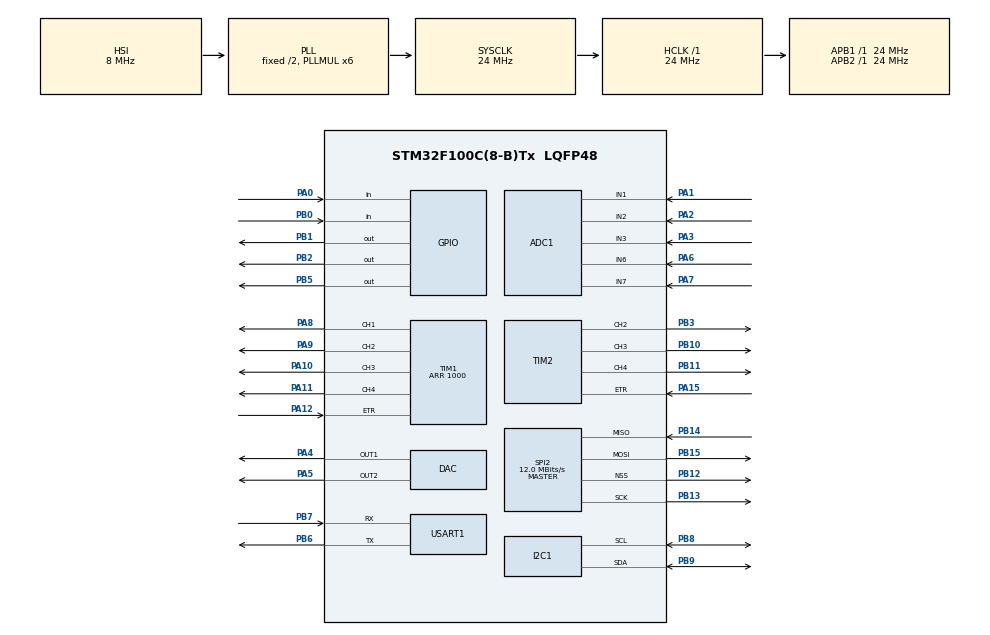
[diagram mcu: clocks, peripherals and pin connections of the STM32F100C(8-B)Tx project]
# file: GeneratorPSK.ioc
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ADC1.Channel-0\#ChannelRegularConversion=ADC_CHANNEL_1
ADC1.Channel-1\#ChannelRegularConversion=ADC_CHANNEL_2
ADC1.Channel-2\#ChannelRegularConversion=ADC_CHANNEL_3
ADC1.Channel-3\#ChannelRegularConversion=ADC_CHANNEL_6
ADC1.Channel-4\#ChannelRegularConversion=ADC_CHANNEL_7
ADC1.NbrOfConversion=5
ADC1.NbrOfConversionFlag=1
ADC1.Rank-0\#ChannelRegularConversion=1
ADC1.Rank-1\#ChannelRegularConversion=2
ADC1.Rank-2\#ChannelRegularConversion=3
ADC1.Rank-3\#ChannelRegularConversion=4
ADC1.Rank-4\#ChannelRegularConversion=5
ADC1.SamplingTime-0\#ChannelRegularConversion=ADC_SAMPLETIME_1CYCLE_5
ADC1.SamplingTime-1\#ChannelRegularConversion=ADC_SAMPLETIME_1CYCLE_5
ADC1.SamplingTime-2\#ChannelRegularConversion=ADC_SAMPLETIME_1CYCLE_5
ADC1.SamplingTime-3\#ChannelRegularConversion=ADC_SAMPLETIME_1CYCLE_5
ADC1.SamplingTime-4\#ChannelRegularConversion=ADC_SAMPLETIME_1CYCLE_5
ADC1.master=1
DAC.DAC_Trigger=DAC_TRIGGER_SOFTWARE
DAC.DAC_Trigger2=DAC_TRIGGER_SOFTWARE
Dma.ADC1.0.Direction=DMA_PERIPH_TO_MEMORY
Dma.ADC1.0.Instance=DMA1_Channel1
Dma.ADC1.0.MemDataAlignment=DMA_MDATAALIGN_HALFWORD
Dma.ADC1.0.MemInc=DMA_MINC_ENABLE
Dma.ADC1.0.Mode=DMA_CIRCULAR
Dma.ADC1.0.PeriphDataAlignment=DMA_PDATAALIGN_HALFWORD
Dma.ADC1.0.PeriphInc=DMA_PINC_DISABLE
Dma.ADC1.0.Priority=DMA_PRIORITY_LOW
Dma.Request0=ADC1
FREERTOS.Tasks01=defaultTask,0,128,StartDefaultTask,Default,NULL,Dynamic,NULL,NULL;userDisplay,-3,128,userDisplayTask,Default,NULL,Dynamic,NULL,NULL
Mcu.Family=STM32F1
Mcu.Name=STM32F100C(8-B)Tx
Mcu.Package=LQFP48
NVIC.DMA1_Channel1_IRQn=true\:5\:0\:false\:false\:true\:true\:false\:true
NVIC.PriorityGroup=NVIC_PRIORITYGROUP_4
NVIC.RCC_IRQn=true\:5\:0\:false\:false\:true\:true\:true\:false
NVIC.TIM1_UP_TIM16_IRQn=true\:5\:0\:false\:false\:true\:true\:true\:true
NVIC.TIM7_IRQn=true\:0\:0\:false\:false\:true\:false\:false\:true
NVIC.TimeBase=TIM7_IRQn
NVIC.TimeBaseIP=TIM7
PA0-WKUP.GPIO_PuPd=GPIO_PULLDOWN
PA0-WKUP.Signal=GPIO_Input
PA1.Signal=ADCx_IN1
PA10.Signal=S_TIM1_CH3
PA11.Signal=S_TIM1_CH4
PA12.Signal=S_TIM1_ETR
PA13.Mode=Serial_Wire
PA13.Signal=SYS_JTMS-SWDIO
PA14.Mode=Serial_Wire
PA14.Signal=SYS_JTCK-SWCLK
PA15.Signal=S_TIM2_CH1_ETR
PA2.Signal=ADCx_IN2
PA3.Signal=ADCx_IN3
PA4.Signal=COMP_DAC1_group
PA5.Signal=COMP_DAC2_group
PA6.Signal=ADCx_IN6
PA7.Signal=ADCx_IN7
PA8.Signal=S_TIM1_CH1
PA9.Signal=S_TIM1_CH2
PB0.Signal=GPIO_Input
PB1.Signal=GPIO_Output
PB10.Signal=S_TIM2_CH3
PB11.Signal=S_TIM2_CH4
PB12.Mode=NSS_Signal_Hard_Output
PB12.Signal=SPI2_NSS
PB13.Mode=Full_Duplex_Master
PB13.Signal=SPI2_SCK
PB14.Mode=Full_Duplex_Master
PB14.Signal=SPI2_MISO
PB15.Mode=Full_Duplex_Master
PB15.Signal=SPI2_MOSI
PB2.Signal=GPIO_Output
PB3.Signal=S_TIM2_CH2
PB5.Signal=GPIO_Output
PB6.Mode=Asynchronous
PB6.Signal=USART1_TX
PB7.Mode=Asynchronous
PB7.Signal=USART1_RX
PB8.Mode=I2C
PB8.Signal=I2C1_SCL
PB9.Mode=I2C
PB9.Signal=I2C1_SDA
ProjectManager.HeapSize=0x200
ProjectManager.StackSize=0x400
ProjectManager.TargetToolchain=SW4STM32
RCC.AHBFreq_Value=24000000
RCC.APB1Freq_Value=24000000
RCC.APB1TimFreq_Value=24000000
RCC.APB2Freq_Value=24000000
RCC.APB2TimFreq_Value=24000000
RCC.HCLKFreq_Value=24000000
RCC.PLLMUL=RCC_PLL_MUL6
RCC.SYSCLKFreq_VALUE=24000000
RCC.SYSCLKSource=RCC_SYSCLKSOURCE_PLLCLK
SH.ADCx_IN1.0=ADC1_IN1,IN1
SH.ADCx_IN2.0=ADC1_IN2,IN2
SH.ADCx_IN3.0=ADC1_IN3,IN3
SH.ADCx_IN6.0=ADC1_IN6,IN6
SH.ADCx_IN7.0=ADC1_IN7,IN7
SH.COMP_DAC1_group.0=DAC_OUT1,DAC_OUT1
SH.COMP_DAC2_group.0=DAC_OUT2,DAC_OUT2
SH.S_TIM1_CH1.0=TIM1_CH1,PWM Generation1 CH1
SH.S_TIM1_CH2.0=TIM1_CH2,PWM Generation2 CH2
SH.S_TIM1_CH3.0=TIM1_CH3,PWM Generation3 CH3
SH.S_TIM1_CH4.0=TIM1_CH4,PWM Generation4 CH4
SH.S_TIM1_ETR.0=TIM1_ETR,ClockSourceETR_Mode2
SH.S_TIM2_CH1_ETR.0=TIM2_ETR,ClockSourceETR_Mode2
SH.S_TIM2_CH2.0=TIM2_CH2,PWM Generation2 CH2
SH.S_TIM2_CH3.0=TIM2_CH3,PWM Generation3 CH3
SH.S_TIM2_CH4.0=TIM2_CH4,PWM Generation4 CH4
SPI2.CalculateBaudRate=12.0 MBits/s
SPI2.Direction=SPI_DIRECTION_2LINES
SPI2.Mode=SPI_MODE_MASTER
SPI2.VirtualNSS=VM_NSSHARD
SPI2.VirtualType=VM_MASTER
TIM1.AutoReloadPreload=TIM_AUTORELOAD_PRELOAD_ENABLE
TIM1.Channel-PWM\ Generation1\ CH1=TIM_CHANNEL_1
TIM1.Channel-PWM\ Generation2\ CH2=TIM_CHANNEL_2
TIM1.Channel-PWM\ Generation3\ CH3=TIM_CHANNEL_3
TIM1.Channel-PWM\ Generation4\ CH4=TIM_CHANNEL_4
TIM1.OCPolarity_1=TIM_OCPOLARITY_LOW
TIM1.OCPolarity_2=TIM_OCPOLARITY_LOW
TIM1.OCPolarity_3=TIM_OCPOLARITY_LOW
TIM1.OCPolarity_4=TIM_OCPOLARITY_LOW
TIM1.Period=1000
TIM1.TIM_MasterOutputTrigger=TIM_TRGO_ENABLE
TIM2.Channel-PWM\ Generation2\ CH2=TIM_CHANNEL_2
TIM2.Channel-PWM\ Generation3\ CH3=TIM_CHANNEL_3
TIM2.Channel-PWM\ Generation4\ CH4=TIM_CHANNEL_4
USART1.VirtualMode=VM_ASYNC
VP_FREERTOS_VS_CMSIS_V1.Mode=CMSIS_V1
VP_SYS_VS_tim7.Mode=TIM7
board=custom

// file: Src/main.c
/* USER CODE BEGIN Header */
/**
  ******************************************************************************
  * @file           : main.c
  * @brief          : Main program body
  ******************************************************************************
  * @attention
  *
  * <h2><center>&copy; Copyright (c) 2020 STMicroelectronics.
  * All rights reserved.</center></h2>
  *
  * This software component is licensed by ST under BSD 3-Clause license,
  * the "License"; You may not use this file except in compliance with the
  * License. You may obtain a copy of the License at:
  *                        opensource.org/licenses/BSD-3-Clause
  *
  ******************************************************************************
  */
/* USER CODE END Header */

#include "main.h"
#include "cmsis_os.h"

/* USER CODE BEGIN Includes */
#include "kernel.h"
/* USER CODE END Includes */

ADC_HandleTypeDef hadc1;
DMA_HandleTypeDef hdma_adc1;

DAC_HandleTypeDef hdac;

I2C_HandleTypeDef hi2c1;

SPI_HandleTypeDef hspi2;

TIM_HandleTypeDef htim1;
TIM_HandleTypeDef htim2;

UART_HandleTypeDef huart1;

osThreadId defaultTaskHandle;
osThreadId userDisplayHandle;

void SystemClock_Config(void);
static void MX_GPIO_Init(void);
static void MX_DMA_Init(void);
static void MX_ADC1_Init(void);
static void MX_DAC_Init(void);
static void MX_TIM1_Init(void);
static void MX_I2C1_Init(void);
static void MX_SPI2_Init(void);
static void MX_TIM2_Init(void);
static void MX_USART1_UART_Init(void);
void StartDefaultTask(void const * argument);
void userDisplayTask(void const * argument);

int main(void)
{

  /* MCU Configuration--------------------------------------------------------*/

  /* Reset of all peripherals, Initializes the Flash interface and the Systick. */
  HAL_Init();

  /* Configure the system clock */
  SystemClock_Config();

  /* Initialize all configured peripherals */
  MX_GPIO_Init();
  MX_DMA_Init();
  MX_ADC1_Init();
  MX_DAC_Init();
  MX_TIM1_Init();
  MX_I2C1_Init();
  MX_SPI2_Init();
  MX_TIM2_Init();
  MX_USART1_UART_Init();
  /* USER CODE BEGIN 2 */
  Kernel_Init(&htim1, &htim2, &hadc1, &hdma_adc1, &hdac);

  /* USER CODE END 2 */

  /* Create the thread(s) */
  /* definition and creation of defaultTask */
  osThreadDef(defaultTask, StartDefaultTask, osPriorityNormal, 0, 128);
  defaultTaskHandle = osThreadCreate(osThread(defaultTask), NULL);

  /* definition and creation of userDisplay */
  osThreadDef(userDisplay, userDisplayTask, osPriorityIdle, 0, 128);
  userDisplayHandle = osThreadCreate(osThread(userDisplay), NULL);

  /* Start scheduler */
  osKernelStart();

  /* We should never get here as control is now taken by the scheduler */

  /* Infinite loop */
  while (1)
  {

  }
}

void SystemClock_Config(void)
{
  RCC_OscInitTypeDef RCC_OscInitStruct = {0};
  RCC_ClkInitTypeDef RCC_ClkInitStruct = {0};
  RCC_PeriphCLKInitTypeDef PeriphClkInit = {0};

  /** Initializes the CPU, AHB and APB busses clocks
  */
  RCC_OscInitStruct.OscillatorType = RCC_OSCILLATORTYPE_HSI;
  RCC_OscInitStruct.HSIState = RCC_HSI_ON;
  RCC_OscInitStruct.HSICalibrationValue = RCC_HSICALIBRATION_DEFAULT;
  RCC_OscInitStruct.PLL.PLLState = RCC_PLL_ON;
  RCC_OscInitStruct.PLL.PLLSource = RCC_PLLSOURCE_HSI_DIV2;
  RCC_OscInitStruct.PLL.PLLMUL = RCC_PLL_MUL6;
  if (HAL_RCC_OscConfig(&RCC_OscInitStruct) != HAL_OK)
  {
    Error_Handler();
  }
  /** Initializes the CPU, AHB and APB busses clocks
  */
  RCC_ClkInitStruct.ClockType = RCC_CLOCKTYPE_HCLK|RCC_CLOCKTYPE_SYSCLK
                              |RCC_CLOCKTYPE_PCLK1|RCC_CLOCKTYPE_PCLK2;
  RCC_ClkInitStruct.SYSCLKSource = RCC_SYSCLKSOURCE_PLLCLK;
  RCC_ClkInitStruct.AHBCLKDivider = RCC_SYSCLK_DIV1;
  RCC_ClkInitStruct.APB1CLKDivider = RCC_HCLK_DIV1;
  RCC_ClkInitStruct.APB2CLKDivider = RCC_HCLK_DIV1;

  if (HAL_RCC_ClockConfig(&RCC_ClkInitStruct, FLASH_LATENCY_0) != HAL_OK)
  {
    Error_Handler();
  }
  PeriphClkInit.PeriphClockSelection = RCC_PERIPHCLK_ADC;
  PeriphClkInit.AdcClockSelection = RCC_ADCPCLK2_DIV2;
  if (HAL_RCCEx_PeriphCLKConfig(&PeriphClkInit) != HAL_OK)
  {
    Error_Handler();
  }
}

static void MX_ADC1_Init(void)
{

  ADC_ChannelConfTypeDef sConfig = {0};

  /** Common config
  */
  hadc1.Instance = ADC1;
  hadc1.Init.ScanConvMode = ADC_SCAN_ENABLE;
  hadc1.Init.ContinuousConvMode = DISABLE;
  hadc1.Init.DiscontinuousConvMode = DISABLE;
  hadc1.Init.ExternalTrigConv = ADC_SOFTWARE_START;
  hadc1.Init.DataAlign = ADC_DATAALIGN_RIGHT;
  hadc1.Init.NbrOfConversion = 5;
  if (HAL_ADC_Init(&hadc1) != HAL_OK)
  {
    Error_Handler();
  }
  /** Configure Regular Channel
  */
  sConfig.Channel = ADC_CHANNEL_1;
  sConfig.Rank = ADC_REGULAR_RANK_1;
  sConfig.SamplingTime = ADC_SAMPLETIME_1CYCLE_5;
  if (HAL_ADC_ConfigChannel(&hadc1, &sConfig) != HAL_OK)
  {
    Error_Handler();
  }
  /** Configure Regular Channel
  */
  sConfig.Channel = ADC_CHANNEL_2;
  sConfig.Rank = ADC_REGULAR_RANK_2;
  if (HAL_ADC_ConfigChannel(&hadc1, &sConfig) != HAL_OK)
  {
    Error_Handler();
  }
  /** Configure Regular Channel
  */
  sConfig.Channel = ADC_CHANNEL_3;
  sConfig.Rank = ADC_REGULAR_RANK_3;
  if (HAL_ADC_ConfigChannel(&hadc1, &sConfig) != HAL_OK)
  {
    Error_Handler();
  }
  /** Configure Regular Channel
  */
  sConfig.Channel = ADC_CHANNEL_6;
  sConfig.Rank = ADC_REGULAR_RANK_4;
  if (HAL_ADC_ConfigChannel(&hadc1, &sConfig) != HAL_OK)
  {
    Error_Handler();
  }
  /** Configure Regular Channel
  */
  sConfig.Channel = ADC_CHANNEL_7;
  sConfig.Rank = ADC_REGULAR_RANK_5;
  if (HAL_ADC_ConfigChannel(&hadc1, &sConfig) != HAL_OK)
  {
    Error_Handler();
  }

}

static void MX_DAC_Init(void)
{

  DAC_ChannelConfTypeDef sConfig = {0};

  /** DAC Initialization
  */
  hdac.Instance = DAC;
  if (HAL_DAC_Init(&hdac) != HAL_OK)
  {
    Error_Handler();
  }
  /** DAC channel OUT1 config
  */
  sConfig.DAC_Trigger = DAC_TRIGGER_SOFTWARE;
  sConfig.DAC_OutputBuffer = DAC_OUTPUTBUFFER_ENABLE;
  if (HAL_DAC_ConfigChannel(&hdac, &sConfig, DAC_CHANNEL_1) != HAL_OK)
  {
    Error_Handler();
  }
  /** DAC channel OUT2 config
  */
  if (HAL_DAC_ConfigChannel(&hdac, &sConfig, DAC_CHANNEL_2) != HAL_OK)
  {
    Error_Handler();
  }

}

static void MX_I2C1_Init(void)
{

  hi2c1.Instance = I2C1;
  hi2c1.Init.ClockSpeed = 100000;
  hi2c1.Init.DutyCycle = I2C_DUTYCYCLE_2;
  hi2c1.Init.OwnAddress1 = 0;
  hi2c1.Init.AddressingMode = I2C_ADDRESSINGMODE_7BIT;
  hi2c1.Init.DualAddressMode = I2C_DUALADDRESS_DISABLE;
  hi2c1.Init.OwnAddress2 = 0;
  hi2c1.Init.GeneralCallMode = I2C_GENERALCALL_DISABLE;
  hi2c1.Init.NoStretchMode = I2C_NOSTRETCH_DISABLE;
  if (HAL_I2C_Init(&hi2c1) != HAL_OK)
  {
    Error_Handler();
  }

}

static void MX_SPI2_Init(void)
{

  /* SPI2 parameter configuration*/
  hspi2.Instance = SPI2;
  hspi2.Init.Mode = SPI_MODE_MASTER;
  hspi2.Init.Direction = SPI_DIRECTION_2LINES;
  hspi2.Init.DataSize = SPI_DATASIZE_8BIT;
  hspi2.Init.CLKPolarity = SPI_POLARITY_LOW;
  hspi2.Init.CLKPhase = SPI_PHASE_1EDGE;
  hspi2.Init.NSS = SPI_NSS_HARD_OUTPUT;
  hspi2.Init.BaudRatePrescaler = SPI_BAUDRATEPRESCALER_2;
  hspi2.Init.FirstBit = SPI_FIRSTBIT_MSB;
  hspi2.Init.TIMode = SPI_TIMODE_DISABLE;
  hspi2.Init.CRCCalculation = SPI_CRCCALCULATION_DISABLE;
  hspi2.Init.CRCPolynomial = 10;
  if (HAL_SPI_Init(&hspi2) != HAL_OK)
  {
    Error_Handler();
  }

}

static void MX_TIM1_Init(void)
{

  TIM_ClockConfigTypeDef sClockSourceConfig = {0};
  TIM_MasterConfigTypeDef sMasterConfig = {0};
  TIM_OC_InitTypeDef sConfigOC = {0};
  TIM_BreakDeadTimeConfigTypeDef sBreakDeadTimeConfig = {0};

  htim1.Instance = TIM1;
  htim1.Init.Prescaler = 0;
  htim1.Init.CounterMode = TIM_COUNTERMODE_UP;
  htim1.Init.Period = 1000;
  htim1.Init.ClockDivision = TIM_CLOCKDIVISION_DIV1;
  htim1.Init.RepetitionCounter = 0;
  htim1.Init.AutoReloadPreload = TIM_AUTORELOAD_PRELOAD_ENABLE;
  if (HAL_TIM_Base_Init(&htim1) != HAL_OK)
  {
    Error_Handler();
  }
  sClockSourceConfig.ClockSource = TIM_CLOCKSOURCE_ETRMODE2;
  sClockSourceConfig.ClockPolarity = TIM_CLOCKPOLARITY_NONINVERTED;
  sClockSourceConfig.ClockPrescaler = TIM_CLOCKPRESCALER_DIV1;
  sClockSourceConfig.ClockFilter = 0;
  if (HAL_TIM_ConfigClockSource(&htim1, &sClockSourceConfig) != HAL_OK)
  {
    Error_Handler();
  }
  if (HAL_TIM_PWM_Init(&htim1) != HAL_OK)
  {
    Error_Handler();
  }
  sMasterConfig.MasterOutputTrigger = TIM_TRGO_ENABLE;
  sMasterConfig.MasterSlaveMode = TIM_MASTERSLAVEMODE_DISABLE;
  if (HAL_TIMEx_MasterConfigSynchronization(&htim1, &sMasterConfig) != HAL_OK)
  {
    Error_Handler();
  }
  sConfigOC.OCMode = TIM_OCMODE_PWM1;
  sConfigOC.Pulse = 0;
  sConfigOC.OCPolarity = TIM_OCPOLARITY_LOW;
  sConfigOC.OCNPolarity = TIM_OCNPOLARITY_HIGH;
  sConfigOC.OCFastMode = TIM_OCFAST_DISABLE;
  sConfigOC.OCIdleState = TIM_OCIDLESTATE_RESET;
  sConfigOC.OCNIdleState = TIM_OCNIDLESTATE_RESET;
  if (HAL_TIM_PWM_ConfigChannel(&htim1, &sConfigOC, TIM_CHANNEL_1) != HAL_OK)
  {
    Error_Handler();
  }
  if (HAL_TIM_PWM_ConfigChannel(&htim1, &sConfigOC, TIM_CHANNEL_2) != HAL_OK)
  {
    Error_Handler();
  }
  if (HAL_TIM_PWM_ConfigChannel(&htim1, &sConfigOC, TIM_CHANNEL_3) != HAL_OK)
  {
    Error_Handler();
  }
  if (HAL_TIM_PWM_ConfigChannel(&htim1, &sConfigOC, TIM_CHANNEL_4) != HAL_OK)
  {
    Error_Handler();
  }
  sBreakDeadTimeConfig.OffStateRunMode = TIM_OSSR_DISABLE;
  sBreakDeadTimeConfig.OffStateIDLEMode = TIM_OSSI_DISABLE;
  sBreakDeadTimeConfig.LockLevel = TIM_LOCKLEVEL_OFF;
  sBreakDeadTimeConfig.DeadTime = 0;
  sBreakDeadTimeConfig.BreakState = TIM_BREAK_DISABLE;
  sBreakDeadTimeConfig.BreakPolarity = TIM_BREAKPOLARITY_HIGH;
  sBreakDeadTimeConfig.AutomaticOutput = TIM_AUTOMATICOUTPUT_DISABLE;
  if (HAL_TIMEx_ConfigBreakDeadTime(&htim1, &sBreakDeadTimeConfig) != HAL_OK)
  {
    Error_Handler();
  }
  HAL_TIM_MspPostInit(&htim1);

}

static void MX_TIM2_Init(void)
{

  TIM_ClockConfigTypeDef sClockSourceConfig = {0};
  TIM_MasterConfigTypeDef sMasterConfig = {0};
  TIM_OC_InitTypeDef sConfigOC = {0};

  htim2.Instance = TIM2;
  htim2.Init.Prescaler = 0;
  htim2.Init.CounterMode = TIM_COUNTERMODE_UP;
  htim2.Init.Period = 0;
  htim2.Init.ClockDivision = TIM_CLOCKDIVISION_DIV1;
  htim2.Init.AutoReloadPreload = TIM_AUTORELOAD_PRELOAD_DISABLE;
  if (HAL_TIM_Base_Init(&htim2) != HAL_OK)
  {
    Error_Handler();
  }
  sClockSourceConfig.ClockSource = TIM_CLOCKSOURCE_ETRMODE2;
  sClockSourceConfig.ClockPolarity = TIM_CLOCKPOLARITY_NONINVERTED;
  sClockSourceConfig.ClockPrescaler = TIM_CLOCKPRESCALER_DIV1;
  sClockSourceConfig.ClockFilter = 0;
  if (HAL_TIM_ConfigClockSource(&htim2, &sClockSourceConfig) != HAL_OK)
  {
    Error_Handler();
  }
  if (HAL_TIM_PWM_Init(&htim2) != HAL_OK)
  {
    Error_Handler();
  }
  sMasterConfig.MasterOutputTrigger = TIM_TRGO_RESET;
  sMasterConfig.MasterSlaveMode = TIM_MASTERSLAVEMODE_DISABLE;
  if (HAL_TIMEx_MasterConfigSynchronization(&htim2, &sMasterConfig) != HAL_OK)
  {
    Error_Handler();
  }
  sConfigOC.OCMode = TIM_OCMODE_PWM1;
  sConfigOC.Pulse = 0;
  sConfigOC.OCPolarity = TIM_OCPOLARITY_HIGH;
  sConfigOC.OCFastMode = TIM_OCFAST_DISABLE;
  if (HAL_TIM_PWM_ConfigChannel(&htim2, &sConfigOC, TIM_CHANNEL_2) != HAL_OK)
  {
    Error_Handler();
  }
  if (HAL_TIM_PWM_ConfigChannel(&htim2, &sConfigOC, TIM_CHANNEL_3) != HAL_OK)
  {
    Error_Handler();
  }
  if (HAL_TIM_PWM_ConfigChannel(&htim2, &sConfigOC, TIM_CHANNEL_4) != HAL_OK)
  {
    Error_Handler();
  }
  HAL_TIM_MspPostInit(&htim2);

}

static void MX_USART1_UART_Init(void)
{

  huart1.Instance = USART1;
  huart1.Init.BaudRate = 115200;
  huart1.Init.WordLength = UART_WORDLENGTH_8B;
  huart1.Init.StopBits = UART_STOPBITS_1;
  huart1.Init.Parity = UART_PARITY_NONE;
  huart1.Init.Mode = UART_MODE_TX_RX;
  huart1.Init.HwFlowCtl = UART_HWCONTROL_NONE;
  huart1.Init.OverSampling = UART_OVERSAMPLING_16;
  if (HAL_UART_Init(&huart1) != HAL_OK)
  {
    Error_Handler();
  }

}

static void MX_DMA_Init(void)
{

  /* DMA controller clock enable */
  __HAL_RCC_DMA1_CLK_ENABLE();

  /* DMA interrupt init */
  /* DMA1_Channel1_IRQn interrupt configuration */
  HAL_NVIC_SetPriority(DMA1_Channel1_IRQn, 5, 0);
  HAL_NVIC_EnableIRQ(DMA1_Channel1_IRQn);

}

static void MX_GPIO_Init(void)
{
  GPIO_InitTypeDef GPIO_InitStruct = {0};

  /* GPIO Ports Clock Enable */
  __HAL_RCC_GPIOA_CLK_ENABLE();
  __HAL_RCC_GPIOB_CLK_ENABLE();

  /*Configure GPIO pin Output Level */
  HAL_GPIO_WritePin(GPIOB, GPIO_PIN_1|GPIO_PIN_2|GPIO_PIN_5, GPIO_PIN_RESET);

  /*Configure GPIO pin : PA0 */
  GPIO_InitStruct.Pin = GPIO_PIN_0;
  GPIO_InitStruct.Mode = GPIO_MODE_INPUT;
  GPIO_InitStruct.Pull = GPIO_PULLDOWN;
  HAL_GPIO_Init(GPIOA, &GPIO_InitStruct);

  /*Configure GPIO pin : PB0 */
  GPIO_InitStruct.Pin = GPIO_PIN_0;
  GPIO_InitStruct.Mode = GPIO_MODE_INPUT;
  GPIO_InitStruct.Pull = GPIO_NOPULL;
  HAL_GPIO_Init(GPIOB, &GPIO_InitStruct);

  /*Configure GPIO pins : PB1 PB2 PB5 */
  GPIO_InitStruct.Pin = GPIO_PIN_1|GPIO_PIN_2|GPIO_PIN_5;
  GPIO_InitStruct.Mode = GPIO_MODE_OUTPUT_PP;
  GPIO_InitStruct.Pull = GPIO_NOPULL;
  GPIO_InitStruct.Speed = GPIO_SPEED_FREQ_LOW;
  HAL_GPIO_Init(GPIOB, &GPIO_InitStruct);

}

void StartDefaultTask(void const * argument)
{
  /* USER CODE BEGIN 5 */

	Kernel_Task();
  /* Infinite loop */
  for(;;)
  {

    osDelay(1);
  }
  /* USER CODE END 5 */
}

void userDisplayTask(void const * argument)
{
  /* USER CODE BEGIN userDisplayTask */
	UserDisplayTask();
  /* Infinite loop */
  for(;;)
  {
    osDelay(1);
  }
  /* USER CODE END userDisplayTask */
}

void HAL_TIM_PeriodElapsedCallback(TIM_HandleTypeDef *htim)
{
  if (htim->Instance == TIM7) {
    HAL_IncTick();
  }
  /* USER CODE BEGIN Callback 1 */
  TIM1_PeriodElapsedCallback();
  /* USER CODE END Callback 1 */
}

void Error_Handler(void)
{
}

/************************ (C) COPYRIGHT STMicroelectronics *****END OF FILE****/
